# CY8C5888LTI_LP097 register map
File version: 0.1
CY8C58LP
Registers are 8-bit, read-write, no defined reset value unless marked. A register's access mark holds for its fields unless they carry their own. Offsets are from the block's base; lines under a group give offsets from that group; [hi:lo] are bit positions; {n}, {i} and the like mark numbered series; 'fields as' and 'values as' point back to an identical list; <NAME> marks a mode.

## Memory map
0x00000000 SysTerminal — UART
0x00000000 RegCtrl
0x00000000 RegInD
0x00000000 RegLsbA
0x00000000 RegMsbA
0x00000000 SysCtrlReg
0x00000000 USB — USBFS
0x00000000 Z80Ctrl_WaitCtrlReg

## SysTerminal — UART
Base 0x00000000
0x40006428 RX_SysTerminal_RX_ADDRESS1 — RX Address1 Register
0x40006438 RX_SysTerminal_RX_ADDRESS2 — RX Address2 Register
0x40006448 RX_SysTerminal_RX_DATA — RX Data Register
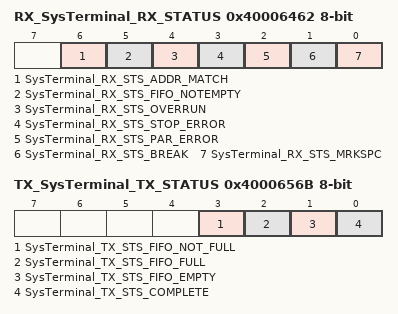
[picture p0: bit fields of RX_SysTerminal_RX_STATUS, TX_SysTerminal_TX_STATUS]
0x40006462 RX_SysTerminal_RX_STATUS — RX status register
  [6] SysTerminal_RX_STS_ADDR_MATCH ro, [5] SysTerminal_RX_STS_FIFO_NOTEMPTY ro, [4] SysTerminal_RX_STS_OVERRUN ro, [3] SysTerminal_RX_STS_STOP_ERROR ro, [2] SysTerminal_RX_STS_PAR_ERROR ro, [1] SysTerminal_RX_STS_BREAK ro, [0] SysTerminal_RX_STS_MRKSPC ro
0x4000654B TX_SysTerminal_TX_DATA — TX Data Register
0x4000656B TX_SysTerminal_TX_STATUS — TX status register
  [3] SysTerminal_TX_STS_FIFO_NOT_FULL ro, [2] SysTerminal_TX_STS_FIFO_FULL ro, [1] SysTerminal_TX_STS_FIFO_EMPTY ro, [0] SysTerminal_TX_STS_COMPLETE ro

## RegCtrl
Base 0x00000000
0x40006466 RegCtrl_STATUS_REG
0x40006486 RegCtrl_MASK_REG
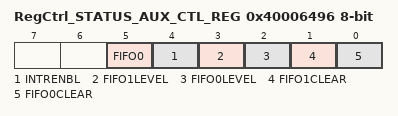
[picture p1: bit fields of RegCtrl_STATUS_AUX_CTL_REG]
0x40006496 RegCtrl_STATUS_AUX_CTL_REG
  [5] FIFO0 — FIFO0 clear
    1=ENABLED (Enable counter); 0=DISABLED (Disable counter)
  [4] INTRENBL — Enables or disables the Interrupt
    1=ENABLED (Interrupt enabled); 0=DISABLED (Interrupt disabled)
  [3] FIFO1LEVEL — FIFO level
    1=ENABLED (FIFO LVL: input mode: FIFO at least 1/2 empty; output mode: FIFO at least 1/2 full); 0=DISABLED (FIFO LVL: input mode: FIFO not full; output mode: FIFO not empty)
  [2] FIFO0LEVEL — FIFO level
    values as FIFO1LEVEL
  [1] FIFO1CLEAR — FIFO clear
    1=ENABLED (Clear FIFO state); 0=DISABLED (Normal FIFO operation)
  [0] FIFO0CLEAR — FIFO clear
    values as FIFO1CLEAR

## RegInD
Base 0x00000000
0x40006460 RegInD_STATUS_REG
0x40006480 RegInD_MASK_REG
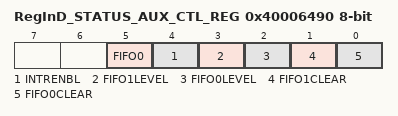
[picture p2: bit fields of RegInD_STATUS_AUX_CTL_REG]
0x40006490 RegInD_STATUS_AUX_CTL_REG
  [5] FIFO0 — FIFO0 clear
    1=ENABLED (Enable counter); 0=DISABLED (Disable counter)
  [4] INTRENBL — Enables or disables the Interrupt
    1=ENABLED (Interrupt enabled); 0=DISABLED (Interrupt disabled)
  [3] FIFO1LEVEL — FIFO level
    1=ENABLED (FIFO LVL: input mode: FIFO at least 1/2 empty; output mode: FIFO at least 1/2 full); 0=DISABLED (FIFO LVL: input mode: FIFO not full; output mode: FIFO not empty)
  [2] FIFO0LEVEL — FIFO level
    values as FIFO1LEVEL
  [1] FIFO1CLEAR — FIFO clear
    1=ENABLED (Clear FIFO state); 0=DISABLED (Normal FIFO operation)
  [0] FIFO0CLEAR — FIFO clear
    values as FIFO1CLEAR

## RegLsbA
Base 0x00000000
0x40006469 RegLsbA_STATUS_REG
0x40006489 RegLsbA_MASK_REG
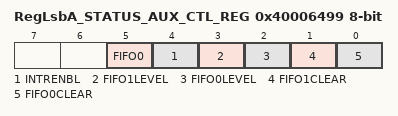
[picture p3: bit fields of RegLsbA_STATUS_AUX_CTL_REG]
0x40006499 RegLsbA_STATUS_AUX_CTL_REG
  [5] FIFO0 — FIFO0 clear
    1=ENABLED (Enable counter); 0=DISABLED (Disable counter)
  [4] INTRENBL — Enables or disables the Interrupt
    1=ENABLED (Interrupt enabled); 0=DISABLED (Interrupt disabled)
  [3] FIFO1LEVEL — FIFO level
    1=ENABLED (FIFO LVL: input mode: FIFO at least 1/2 empty; output mode: FIFO at least 1/2 full); 0=DISABLED (FIFO LVL: input mode: FIFO not full; output mode: FIFO not empty)
  [2] FIFO0LEVEL — FIFO level
    values as FIFO1LEVEL
  [1] FIFO1CLEAR — FIFO clear
    1=ENABLED (Clear FIFO state); 0=DISABLED (Normal FIFO operation)
  [0] FIFO0CLEAR — FIFO clear
    values as FIFO1CLEAR

## RegMsbA
Base 0x00000000
0x40006564 RegMsbA_STATUS_REG
0x40006584 RegMsbA_MASK_REG
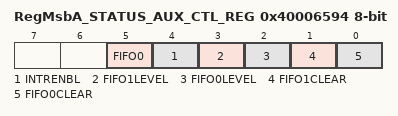
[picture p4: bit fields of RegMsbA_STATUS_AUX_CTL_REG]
0x40006594 RegMsbA_STATUS_AUX_CTL_REG
  [5] FIFO0 — FIFO0 clear
    1=ENABLED (Enable counter); 0=DISABLED (Disable counter)
  [4] INTRENBL — Enables or disables the Interrupt
    1=ENABLED (Interrupt enabled); 0=DISABLED (Interrupt disabled)
  [3] FIFO1LEVEL — FIFO level
    1=ENABLED (FIFO LVL: input mode: FIFO at least 1/2 empty; output mode: FIFO at least 1/2 full); 0=DISABLED (FIFO LVL: input mode: FIFO not full; output mode: FIFO not empty)
  [2] FIFO0LEVEL — FIFO level
    values as FIFO1LEVEL
  [1] FIFO1CLEAR — FIFO clear
    1=ENABLED (Clear FIFO state); 0=DISABLED (Normal FIFO operation)
  [0] FIFO0CLEAR — FIFO clear
    values as FIFO1CLEAR
